CM_ "IMPORT _subaru_global_2017.dbc"

BO_ 39 Cruise_Status_2: 8 XXX
 SG_ Cruise_Activated : 37|1@0+ (1,0) [0|1] "" XXX

BO_ 295 Transmission: 8 XXX
 SG_ Gear : 44|4@1+ (1,0) [0|15] "" XXX

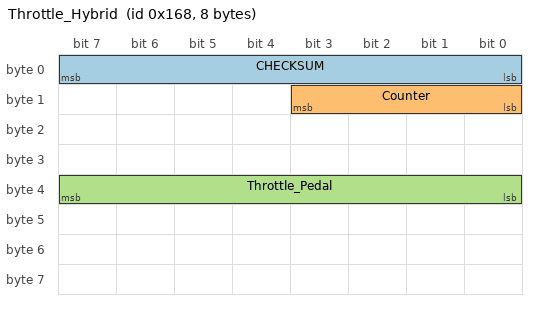
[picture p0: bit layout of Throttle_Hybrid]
BO_ 360 Throttle_Hybrid: 8 XXX
 SG_ CHECKSUM : 0|8@1+ (1,0) [0|255] "" XXX
 SG_ Counter : 8|4@1+ (1,0) [0|15] "" XXX
 SG_ Throttle_Pedal : 32|8@1+ (1,0) [0|255] "" XXX

VAL_ 295 Gear 0 "P" 1 "R" 3 "D";
